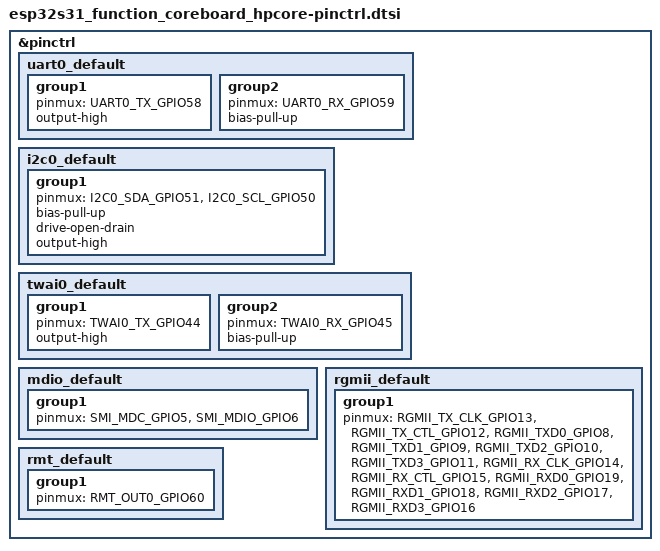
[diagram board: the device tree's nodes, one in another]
/*
 * Copyright (c) 2026 Espressif Systems (Shanghai) Co., Ltd.
 *
 * SPDX-License-Identifier: Apache-2.0
 */

#include <zephyr/dt-bindings/pinctrl/esp32s31-pinctrl.h>

/* Console UART on the default UART0 pads (U0TXD GPIO58, U0RXD GPIO59),
 * which the on-board USB-to-UART bridge is wired to.
 */
&pinctrl {
	uart0_default: uart0_default {
		group1 {
			pinmux = <UART0_TX_GPIO58>;
			output-high;
		};

		group2 {
			pinmux = <UART0_RX_GPIO59>;
			bias-pull-up;
		};
	};

	i2c0_default: i2c0_default {
		group1 {
			pinmux = <I2C0_SDA_GPIO51>,
				 <I2C0_SCL_GPIO50>;
			bias-pull-up;
			drive-open-drain;
			output-high;
		};
	};

	twai0_default: twai0_default {
		group1 {
			pinmux = <TWAI0_TX_GPIO44>;
			output-high;
		};

		group2 {
			pinmux = <TWAI0_RX_GPIO45>;
			bias-pull-up;
		};
	};

	mdio_default: mdio_default {
		group1 {
			pinmux = <SMI_MDC_GPIO5>,
				 <SMI_MDIO_GPIO6>;
		};
	};

	rgmii_default: rgmii_default {
		group1 {
			pinmux = <RGMII_TX_CLK_GPIO13>,
				 <RGMII_TX_CTL_GPIO12>,
				 <RGMII_TXD0_GPIO8>,
				 <RGMII_TXD1_GPIO9>,
				 <RGMII_TXD2_GPIO10>,
				 <RGMII_TXD3_GPIO11>,
				 <RGMII_RX_CLK_GPIO14>,
				 <RGMII_RX_CTL_GPIO15>,
				 <RGMII_RXD0_GPIO19>,
				 <RGMII_RXD1_GPIO18>,
				 <RGMII_RXD2_GPIO17>,
				 <RGMII_RXD3_GPIO16>;
		};
	};

	rmt_default: rmt_default {
		group1 {
			pinmux = <RMT_OUT0_GPIO60>;
		};
	};
};
